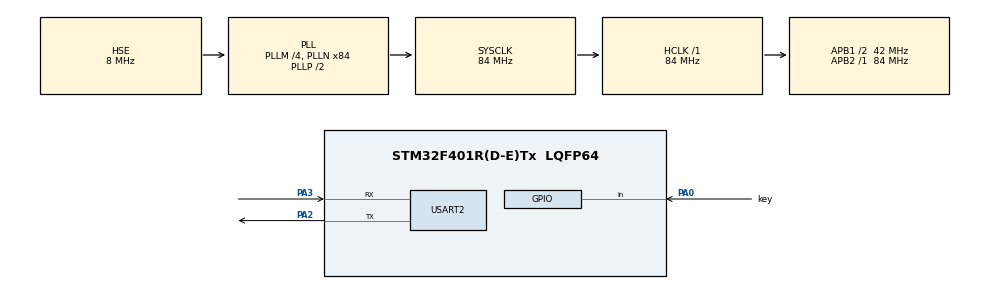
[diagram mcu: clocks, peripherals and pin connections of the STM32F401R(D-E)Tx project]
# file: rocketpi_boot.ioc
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Mcu.Family=STM32F4
Mcu.Name=STM32F401R(D-E)Tx
Mcu.Package=LQFP64
NVIC.PriorityGroup=NVIC_PRIORITYGROUP_4
PA0-WKUP.GPIO_Label=key
PA0-WKUP.Signal=GPIO_Input
PA13.Mode=Serial_Wire
PA13.Signal=SYS_JTMS-SWDIO
PA14.Mode=Serial_Wire
PA14.Signal=SYS_JTCK-SWCLK
PA2.Mode=Asynchronous
PA2.Signal=USART2_TX
PA3.Mode=Asynchronous
PA3.Signal=USART2_RX
PH0\ -\ OSC_IN.Mode=HSE-External-Oscillator
PH0\ -\ OSC_IN.Signal=RCC_OSC_IN
PH1\ -\ OSC_OUT.Mode=HSE-External-Oscillator
PH1\ -\ OSC_OUT.Signal=RCC_OSC_OUT
ProjectManager.HeapSize=0x400
ProjectManager.StackSize=0x2000
ProjectManager.TargetToolchain=MDK-ARM V5.27
RCC.48MHZClocksFreq_Value=42000000
RCC.AHBFreq_Value=84000000
RCC.APB1CLKDivider=RCC_HCLK_DIV2
RCC.APB1Freq_Value=42000000
RCC.APB1TimFreq_Value=84000000
RCC.APB2Freq_Value=84000000
RCC.APB2TimFreq_Value=84000000
RCC.CortexFreq_Value=84000000
RCC.HCLKFreq_Value=84000000
RCC.HSE_VALUE=8000000
RCC.HSI_VALUE=16000000
RCC.LSE_VALUE=32768
RCC.PLLM=4
RCC.PLLN=84
RCC.PLLSourceVirtual=RCC_PLLSOURCE_HSE
RCC.SYSCLKFreq_VALUE=84000000
RCC.SYSCLKSource=RCC_SYSCLKSOURCE_PLLCLK
RCC.VCOOutputFreq_Value=168000000
USART2.VirtualMode=VM_ASYNC
board=custom

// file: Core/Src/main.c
/* USER CODE BEGIN Header */
/**
  ******************************************************************************
  * @file           : main.c
  * @brief          : Main program body
  ******************************************************************************
  * @attention
  *
  * Copyright (c) 2025 STMicroelectronics.
  * All rights reserved.
  *
  * This software is licensed under terms that can be found in the LICENSE file
  * in the root directory of this software component.
  * If no LICENSE file comes with this software, it is provided AS-IS.
  *
  ******************************************************************************
  */
/* USER CODE END Header */
#include "main.h"
#include "usart.h"
#include "gpio.h"

/* USER CODE BEGIN Includes */
#include <stdbool.h>
#include <stdio.h>
#include "ymodem.h"
/* USER CODE END Includes */

/* USER CODE BEGIN PTD */
typedef void (*AppEntryFunction)(void);
/* USER CODE END PTD */

/* USER CODE BEGIN PD */
#define APP_START_ADDRESS     (0x08020000UL)
#define APP_MAX_SIZE_BYTES    (0x60000UL)
#define APP_END_ADDRESS       (APP_START_ADDRESS + APP_MAX_SIZE_BYTES)
#define SRAM_START_ADDRESS    (0x20000000UL)
#define SRAM_SIZE_BYTES       (96UL * 1024UL)
#define SRAM_END_ADDRESS      (SRAM_START_ADDRESS + SRAM_SIZE_BYTES)
#define BOOT_KEY_GPIO_PORT    key_GPIO_Port
#define BOOT_KEY_GPIO_PIN     key_Pin
#define BOOT_KEY_PRESSED_STATE GPIO_PIN_SET
#define BOOT_KEY_SAMPLE_PERIOD_MS (20U)
#define BOOT_KEY_DETECTION_WINDOW_MS (5000UL)
/* USER CODE END PD */

void SystemClock_Config(void);
/* USER CODE BEGIN PFP */
static bool Bootloader_IsApplicationValid(void);
static void Bootloader_JumpToApplication(void);
static bool Bootloader_IsKeyPressed(void);
static bool Bootloader_ShouldEnterUpgradeMode(void);
static void Bootloader_RunUpgradeMode(void);
static void Bootloader_DeInitPeripherals(void);
/* USER CODE END PFP */

/* USER CODE BEGIN 0 */
static bool Bootloader_IsApplicationValid(void)
{
  uint32_t appStackPointer = *(__IO uint32_t *)(APP_START_ADDRESS);
  uint32_t appResetHandler = *(__IO uint32_t *)(APP_START_ADDRESS + 4U);

  bool stackPointerInRange = (appStackPointer >= SRAM_START_ADDRESS) && (appStackPointer <= SRAM_END_ADDRESS);
  bool resetHandlerInRange = (appResetHandler >= APP_START_ADDRESS) && (appResetHandler <= APP_END_ADDRESS);

  return stackPointerInRange && resetHandlerInRange;
}

static void Bootloader_JumpToApplication(void)
{
  uint32_t appStackPointer = *(__IO uint32_t *)(APP_START_ADDRESS);
  uint32_t appResetHandler = *(__IO uint32_t *)(APP_START_ADDRESS + 4U);
  AppEntryFunction application = (AppEntryFunction)appResetHandler;

  __disable_irq();
  Bootloader_DeInitPeripherals();
  HAL_RCC_DeInit();
  HAL_DeInit();
  SysTick->CTRL = 0U;
  SysTick->LOAD = 0U;
  SysTick->VAL = 0U;
  __set_MSP(appStackPointer);
  SCB->VTOR = APP_START_ADDRESS;
  __enable_irq();

  application();
}

static bool Bootloader_IsKeyPressed(void)
{
  return HAL_GPIO_ReadPin(BOOT_KEY_GPIO_PORT, BOOT_KEY_GPIO_PIN) == BOOT_KEY_PRESSED_STATE;
}

static bool Bootloader_ShouldEnterUpgradeMode(void)
{
  uint32_t startTick = HAL_GetTick();

  if (Bootloader_IsKeyPressed())
  {
    printf("[BOOT] Upgrade key pressed at startup.\r\n");
    return true;
  }

  printf("[BOOT] Waiting up to %lu ms for upgrade key...\r\n", (unsigned long)BOOT_KEY_DETECTION_WINDOW_MS);

  while ((HAL_GetTick() - startTick) < BOOT_KEY_DETECTION_WINDOW_MS)
  {
    if (Bootloader_IsKeyPressed())
    {
      printf("[BOOT] Upgrade request detected (elapsed %lu ms).\r\n", (unsigned long)(HAL_GetTick() - startTick));
      return true;
    }
    HAL_Delay(BOOT_KEY_SAMPLE_PERIOD_MS);
  }

  printf("[BOOT] No upgrade request detected.\r\n");
  return false;
}

static void Bootloader_RunUpgradeMode(void)
{
  printf("[BOOT] Entering YMODEM upgrade mode.\r\n");

  while (1)
  {
    ymodem_recv("");
    printf("[BOOT] YMODEM session finished.\r\n");

    if (Bootloader_IsApplicationValid())
    {
      printf("[BOOT] Firmware valid, jumping to application.\r\n");
      Bootloader_JumpToApplication();
    }

    printf("[BOOT] Firmware invalid or upgrade aborted, waiting for another transfer.\r\n");
    HAL_Delay(500U);
  }
}

static void Bootloader_DeInitPeripherals(void)
{
  HAL_UART_DeInit(&huart2);
  HAL_GPIO_DeInit(key_GPIO_Port, key_Pin);
}
/* USER CODE END 0 */

int main(void)
{

  /* MCU Configuration--------------------------------------------------------*/

  /* Reset of all peripherals, Initializes the Flash interface and the Systick. */
  HAL_Init();

  /* Configure the system clock */
  SystemClock_Config();

  /* Initialize all configured peripherals */
  MX_GPIO_Init();
  MX_USART2_UART_Init();
  /* USER CODE BEGIN 2 */
  printf("\r\n[BOOT] RocketPi bootloader started.\r\n");

  bool enterUpgrade = Bootloader_ShouldEnterUpgradeMode();

  if (!enterUpgrade)
  {
    if (Bootloader_IsApplicationValid())
    {
      printf("[BOOT] Jumping to application.\r\n");
      Bootloader_JumpToApplication();
    }
    else
    {
      printf("[BOOT] No valid application found, forcing upgrade mode.\r\n");
      enterUpgrade = true;
    }
  }

  if (enterUpgrade)
  {
    Bootloader_RunUpgradeMode();
  }
  /* USER CODE END 2 */

  /* Infinite loop */
  /* USER CODE BEGIN WHILE */
  while (1)
  {
    HAL_Delay(1000);
    /* USER CODE END WHILE */

  }
}

void SystemClock_Config(void)
{
  RCC_OscInitTypeDef RCC_OscInitStruct = {0};
  RCC_ClkInitTypeDef RCC_ClkInitStruct = {0};

  /** Configure the main internal regulator output voltage
  */
  __HAL_RCC_PWR_CLK_ENABLE();
  __HAL_PWR_VOLTAGESCALING_CONFIG(PWR_REGULATOR_VOLTAGE_SCALE2);

  /** Initializes the RCC Oscillators according to the specified parameters
  * in the RCC_OscInitTypeDef structure.
  */
  RCC_OscInitStruct.OscillatorType = RCC_OSCILLATORTYPE_HSE;
  RCC_OscInitStruct.HSEState = RCC_HSE_ON;
  RCC_OscInitStruct.PLL.PLLState = RCC_PLL_ON;
  RCC_OscInitStruct.PLL.PLLSource = RCC_PLLSOURCE_HSE;
  RCC_OscInitStruct.PLL.PLLM = 4;
  RCC_OscInitStruct.PLL.PLLN = 84;
  RCC_OscInitStruct.PLL.PLLP = RCC_PLLP_DIV2;
  RCC_OscInitStruct.PLL.PLLQ = 4;
  if (HAL_RCC_OscConfig(&RCC_OscInitStruct) != HAL_OK)
  {
    Error_Handler();
  }

  /** Initializes the CPU, AHB and APB buses clocks
  */
  RCC_ClkInitStruct.ClockType = RCC_CLOCKTYPE_HCLK|RCC_CLOCKTYPE_SYSCLK
                              |RCC_CLOCKTYPE_PCLK1|RCC_CLOCKTYPE_PCLK2;
  RCC_ClkInitStruct.SYSCLKSource = RCC_SYSCLKSOURCE_PLLCLK;
  RCC_ClkInitStruct.AHBCLKDivider = RCC_SYSCLK_DIV1;
  RCC_ClkInitStruct.APB1CLKDivider = RCC_HCLK_DIV2;
  RCC_ClkInitStruct.APB2CLKDivider = RCC_HCLK_DIV1;

  if (HAL_RCC_ClockConfig(&RCC_ClkInitStruct, FLASH_LATENCY_2) != HAL_OK)
  {
    Error_Handler();
  }
}

void Error_Handler(void)
{
  __disable_irq();
  while (1)
  {
  }
}
